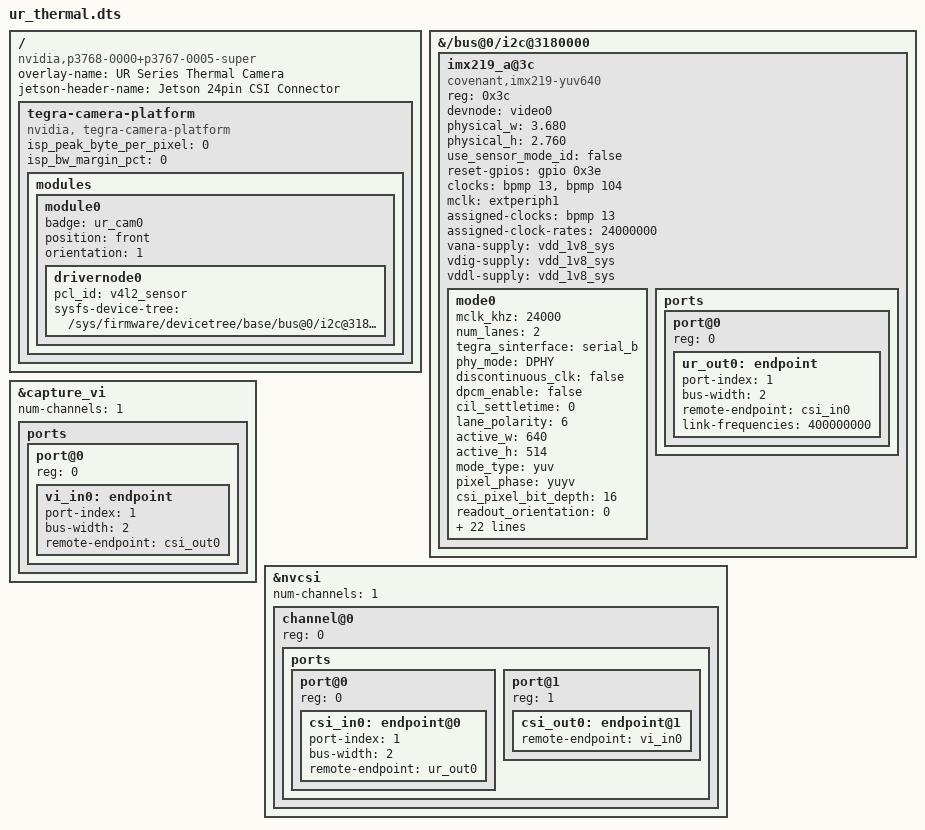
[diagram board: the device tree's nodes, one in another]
/dts-v1/;
/plugin/;

/ {
    overlay-name = "UR Series Thermal Camera";
    jetson-header-name = "Jetson 24pin CSI Connector";
    compatible = "nvidia,p3768-0000+p3767-0005-super", "nvidia,p3767-0005", "nvidia,tegra234";

    /* Fragment 0: Platform Configuration */
    fragment@0 {
        target-path = "/";
        __overlay__ {
            tegra-camera-platform {
                compatible = "nvidia, tegra-camera-platform";
                /* Bypass ISP: set bandwidths to 0 */
                isp_peak_byte_per_pixel = <0>;
                isp_bw_margin_pct = <0>;
                
                modules {
                    module0 {
                        badge = "ur_cam0";
                        position = "front";
                        orientation = "1";
                        drivernode0 {
                            pcl_id = "v4l2_sensor";
                            /* Point to the specific I2C bus device node */
                            sysfs-device-tree = "/sys/firmware/devicetree/base/bus@0/i2c@3180000/imx219_a@3c";
                        };
                    };
                };
            };
        };
    };

    /* Fragment 1: Sensor Definition */
    /* Target 'cam_i2c' maps to /bus@0/i2c@3180000 on Orin Nano */
    fragment@1 {
        target-path = "/bus@0/i2c@3180000";
        __overlay__ {
            status = "okay";
            #address-cells = <1>;
            #size-cells = <0>;

            imx219_a@3c {
                compatible = "covenant,imx219-yuv640";
                reg = <0x3c>;
                status = "okay";
                devnode = "video0";
		physical_w = "3.680";
		physical_h = "2.760";
		
		use_sensor_mode_id = "false";
                /* GPIO 62 (0x3e) matches the working camera dump provided */
                reset-gpios = <&gpio 0x3e 0x00>; 

                /* Standard Orin Nano Camera Clocks */
                clocks = <&bpmp 13>, <&bpmp 104>;
                clock-names = "extperiph1", "pll_p_out0";
                mclk = "extperiph1";
                assigned-clocks = <&bpmp 13>;
                assigned-clock-rates = <24000000>;

                /* Power Supplies */
                vana-supply = <&vdd_1v8_sys>;
                vdig-supply = <&vdd_1v8_sys>;
                vddl-supply = <&vdd_1v8_sys>;
			/*mode0 {
			    /*mclk_khz = "24000";
			    num_lanes = "2";
			    tegra_sinterface = "serial_b";
			    phy_mode = "DPHY";
			    discontinuous_clk = "yes";
			    cil_settletime = "0";
			
			    lane_polarity = "6";   // <-- THIS is the key fix for CAM0 on devkit wiring
			
			    active_w = "640";
			    active_h = "512";
			
			    mode_type = "yuv";
			    pixel_phase = "yuyv";
			    csi_pixel_bit_depth = "16";
			
			    // keep your pix_clk_hz for now; polarity is the first blocker
			    pix_clk_hz = "182400000";
			
			    embedded_metadata_height = "0";
			};*/
		mode0 { /* CS307_MODE_640X514_30FPS */
                    mclk_khz = "24000";
                    num_lanes = "2";
                    tegra_sinterface = "serial_b";
                    phy_mode = "DPHY";
                    discontinuous_clk = "false";
                    dpcm_enable = "false";
                    cil_settletime = "0";
                    lane_polarity = "6";
                    active_w = "640";
                    active_h = "514";
                    mode_type = "yuv";
                    pixel_phase = "yuyv";
                    csi_pixel_bit_depth = "16";
                    readout_orientation = "0";
                    line_length = "2200";
                    inherent_gain = "1";
                    mclk_multiplier = "2";
                    pix_clk_hz = "100000000";
                    gain_factor = "16";
                    framerate_factor = "1000000";
                    exposure_factor = "1000000";
                    min_gain_val = "16"; /* 1.00x */
                    max_gain_val = "170"; /* 10.66x */
                    step_gain_val = "1";
                    default_gain = "16"; /* 1.00x */
                    min_hdr_ratio = "1";
                    max_hdr_ratio = "1";
                    min_framerate = "2000000"; /* 2.0 fps */
                    max_framerate = "30000000"; /* 30 fps */
                    step_framerate = "1000000";
                    default_framerate = "30000000"; /* 30 fps */
                    min_exp_time = "13"; /* us */
                    max_exp_time = "333333"; /* us */
                    step_exp_time = "1";
                    default_exp_time = "2495"; /* us */
                    embedded_metadata_height = "0";
                };



                ports {
                    #address-cells = <1>;
                    #size-cells = <0>;
                    port@0 {
                        reg = <0>;
                        ur_out0: endpoint {
                            port-index = <1>; /* CSI B */
                            bus-width = <2>;
                            remote-endpoint = <&csi_in0>;
                            /* 80 MHz Link Frequency */
                             link-frequencies = /bits/ 64 <400000000>;
                            //link-frequencies = <456000000>;

                        };
                    };
                };
            };
        };
    };

    /* Fragment 2: Enable VI Port */
    fragment@2 {
        target = <&capture_vi>;
        __overlay__ {
            num-channels = <1>;
            ports {
                #address-cells = <1>;
                #size-cells = <0>;
                port@0 {
                    reg = <0>;
                    vi_in0: endpoint {
                        port-index = <1>; /* Port 1 */
                        bus-width = <2>;
                        remote-endpoint = <&csi_out0>;
                    };
                };
            };
        };
    };

    /* Fragment 3: Enable CSI Port and link to Sensor */
    fragment@3 {
        target = <&nvcsi>;
        __overlay__ {
            num-channels = <1>;
            #address-cells = <1>;
            #size-cells = <0>;
            channel@0 {
                reg = <0>;
                ports {
                    #address-cells = <1>;
                    #size-cells = <0>;
                    port@0 {
                        reg = <0>;
                        csi_in0: endpoint@0 {
                            port-index = <1>; /* CSI B */
                            bus-width = <2>;
                            remote-endpoint = <&ur_out0>;
                        };
                    };
                    port@1 {
                        reg = <1>;
                        csi_out0: endpoint@1 {
                            remote-endpoint = <&vi_in0>;
                        };
                    };
                };
            };
        };
    };
};
